# STM32F303 register map
File version: 1.4
CPU: CM4 r1p0, little endian, no MPU, no FPU, 4 interrupt priority bits
Registers are 32-bit, read-write, reset 0x0 unless marked. A register's access mark holds for its fields unless they carry their own. Offsets are from the block's base; [hi:lo] are bit positions; 'fields as' and 'values as' point back to an identical list.

## DAC1 — Digital-to-analog converter
Base 0x40007400
Same registers: DAC2 0x40009800
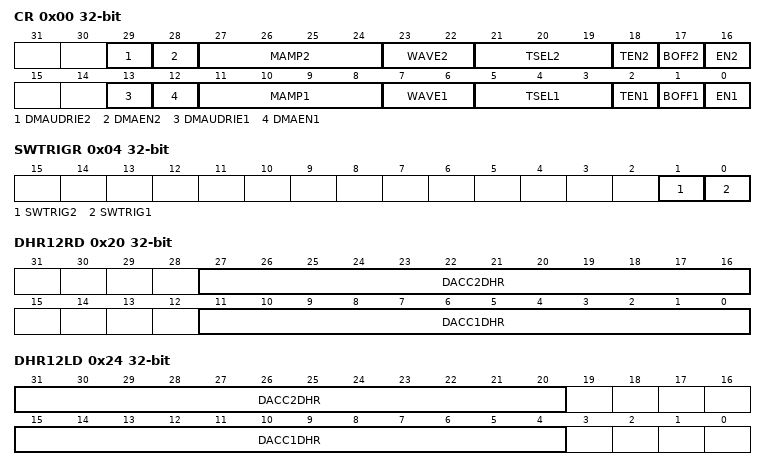
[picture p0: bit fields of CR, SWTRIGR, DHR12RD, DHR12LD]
0x00 CR — control register
  [29] DMAUDRIE2 — DAC channel2 DMA underrun interrupt enable
    0=Disabled (DAC channel X DMA Underrun Interrupt disabled); 1=Enabled (DAC channel X DMA Underrun Interrupt enabled)
  [28] DMAEN2 — DAC channel2 DMA enable
    0=Disabled (DAC channel X DMA mode disabled); 1=Enabled (DAC channel X DMA mode enabled)
  [27:24] MAMP2 — DAC channel2 mask/amplitude selector
  [23:22] WAVE2 — DAC channel2 noise/triangle wave generation enable
    0=Disabled (Wave generation disabled); 1=Noise wave generation enabled; 2=Triangle wave generation enabled
  [21:19] TSEL2 — DAC channel2 trigger selection
    0=TIM6_TRGO (Timer 6 TRGO event); 1=TIM8_TRGO (Timer 8 TRGO event); 2=TIM7_TRGO (Timer 7 TRGO event); 3=TIM5_TRGO (Timer 5 TRGO event); 4=TIM2_TRGO (Timer 2 TRGO event); 5=TIM4_TRGO (Timer 4 TRGO event); 6=EXTI9 (EXTI line9); 7=SOFTWARE (Software trigger)
  [18] TEN2 — DAC channel2 trigger enable
    0=Disabled (DAC channel X trigger disabled); 1=Enabled (DAC channel X trigger enabled)
  [17] BOFF2 — DAC channel2 output buffer disable
    0=Enabled (DAC channel X output buffer enabled); 1=Disabled (DAC channel X output buffer disabled)
  [16] EN2 — DAC channel2 enable
    0=Disabled (DAC channel X disabled); 1=Enabled (DAC channel X enabled)
  [13] DMAUDRIE1 — DAC channel1 DMA Underrun Interrupt enable
    values as DMAUDRIE2
  [12] DMAEN1 — DAC channel1 DMA enable
    values as DMAEN2
  [11:8] MAMP1 — DAC channel1 mask/amplitude selector
  [7:6] WAVE1 — DAC channel1 noise/triangle wave generation enable
    values as WAVE2
  [5:3] TSEL1 — DAC channel1 trigger selection
    0=TIM6_TRGO (Timer 6 TRGO event); 1=TIM3_TRGO (Timer 3 TRGO event); 2=TIM7_TRGO (Timer 7 TRGO event); 3=TIM15_TRGO (Timer 15 TRGO event); 4=TIM2_TRGO (Timer 2 TRGO event); 6=EXTI9 (EXTI line9); 7=SOFTWARE (Software trigger)
  [2] TEN1 — DAC channel1 trigger enable
    values as TEN2
  [1] BOFF1 — DAC channel1 output buffer disable
    values as BOFF2
  [0] EN1 — DAC channel1 enable
    values as EN2
0x04 SWTRIGR wo — software trigger register
  [1] SWTRIG2 — DAC channel2 software trigger
    0=Disabled (DAC channel X software trigger disabled); 1=Enabled (DAC channel X software trigger enabled)
  [0] SWTRIG1 — DAC channel1 software trigger
    values as SWTRIG2
0x08 DHR12R1 — channel1 12-bit right-aligned data holding register
  [11:0] DACC1DHR — DAC channel1 12-bit right-aligned data
0x0C DHR12L1 — channel1 12-bit left aligned data holding register
  [15:4] DACC1DHR — DAC channel1 12-bit left-aligned data
0x10 DHR8R1 — channel1 8-bit right aligned data holding register
  [7:0] DACC1DHR — DAC channel1 8-bit right-aligned data
0x14 DHR12R2 — channel2 12-bit right aligned data holding register
  [11:0] DACC2DHR — DAC channel2 12-bit right-aligned data
0x18 DHR12L2 — channel2 12-bit left aligned data holding register
  [15:4] DACC2DHR — DAC channel2 12-bit left-aligned data
0x1C DHR8R2 — channel2 8-bit right-aligned data holding register
  [7:0] DACC2DHR — DAC channel2 8-bit right-aligned data
0x20 DHR12RD — Dual DAC 12-bit right-aligned data holding register
  [27:16] DACC2DHR — DAC channel2 12-bit right-aligned data
  [11:0] DACC1DHR — DAC channel1 12-bit right-aligned data
0x24 DHR12LD — DUAL DAC 12-bit left aligned data holding register
  [31:20] DACC2DHR — DAC channel2 12-bit left-aligned data
  [15:4] DACC1DHR — DAC channel1 12-bit left-aligned data
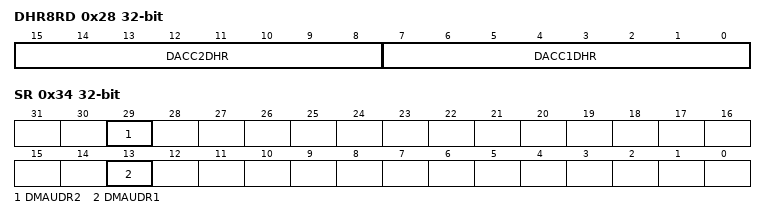
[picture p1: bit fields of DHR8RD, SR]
0x28 DHR8RD — DUAL DAC 8-bit right aligned data holding register
  [15:8] DACC2DHR — DAC channel2 8-bit right-aligned data
  [7:0] DACC1DHR — DAC channel1 8-bit right-aligned data
0x2C DOR1 ro — channel1 data output register
  [11:0] DACC1DOR — DAC channel1 data output
0x30 DOR2 ro — channel2 data output register
  [11:0] DACC2DOR — DAC channel2 data output
0x34 SR — status register
  [29] DMAUDR2 — DAC channel2 DMA underrun flag
    0=NoUnderrun (No DMA underrun error condition occurred for DAC channel X); 1=Underrun (DMA underrun error condition occurred for DAC channel X)
  [13] DMAUDR1 — DAC channel1 DMA underrun flag
    values as DMAUDR2
